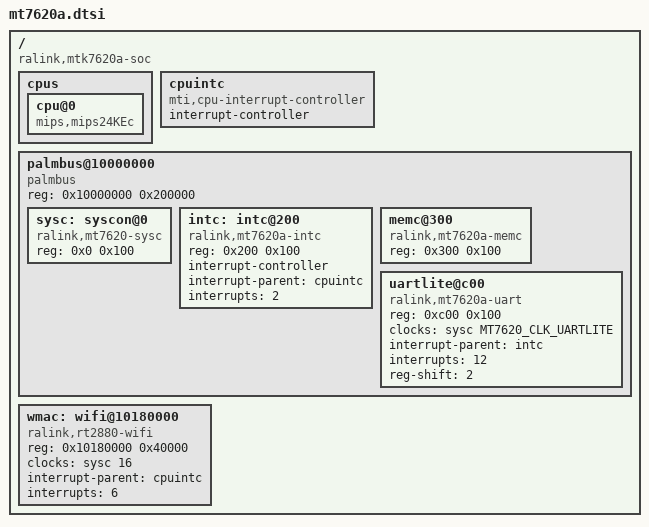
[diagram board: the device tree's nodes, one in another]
// SPDX-License-Identifier: GPL-2.0
#include <dt-bindings/clock/mediatek,mtmips-sysc.h>

/ {
	#address-cells = <1>;
	#size-cells = <1>;
	compatible = "ralink,mtk7620a-soc";

	cpus {
		cpu@0 {
			compatible = "mips,mips24KEc";
		};
	};

	cpuintc: cpuintc {
		#address-cells = <0>;
		#interrupt-cells = <1>;
		interrupt-controller;
		compatible = "mti,cpu-interrupt-controller";
	};

	palmbus@10000000 {
		compatible = "palmbus";
		reg = <0x10000000 0x200000>;
                ranges = <0x0 0x10000000 0x1FFFFF>;

		#address-cells = <1>;
		#size-cells = <1>;

		sysc: syscon@0 {
			compatible = "ralink,mt7620-sysc", "syscon";
			reg = <0x0 0x100>;
			#clock-cells = <1>;
			#reset-cells = <1>;
		};

		intc: intc@200 {
			compatible = "ralink,mt7620a-intc", "ralink,rt2880-intc";
			reg = <0x200 0x100>;

			interrupt-controller;
			#interrupt-cells = <1>;

			interrupt-parent = <&cpuintc>;
			interrupts = <2>;
		};

		memc@300 {
			compatible = "ralink,mt7620a-memc", "ralink,rt3050-memc";
			reg = <0x300 0x100>;
		};

		uartlite@c00 {
			compatible = "ralink,mt7620a-uart", "ralink,rt2880-uart", "ns16550a";
			reg = <0xc00 0x100>;

			clocks = <&sysc MT7620_CLK_UARTLITE>;

			interrupt-parent = <&intc>;
			interrupts = <12>;

			reg-shift = <2>;
		};
	};

	wmac: wifi@10180000 {
		compatible = "ralink,rt2880-wifi";
		reg = <0x10180000 0x40000>;

		clocks = <&sysc 16>;

		interrupt-parent = <&cpuintc>;
		interrupts = <6>;
	};
};
